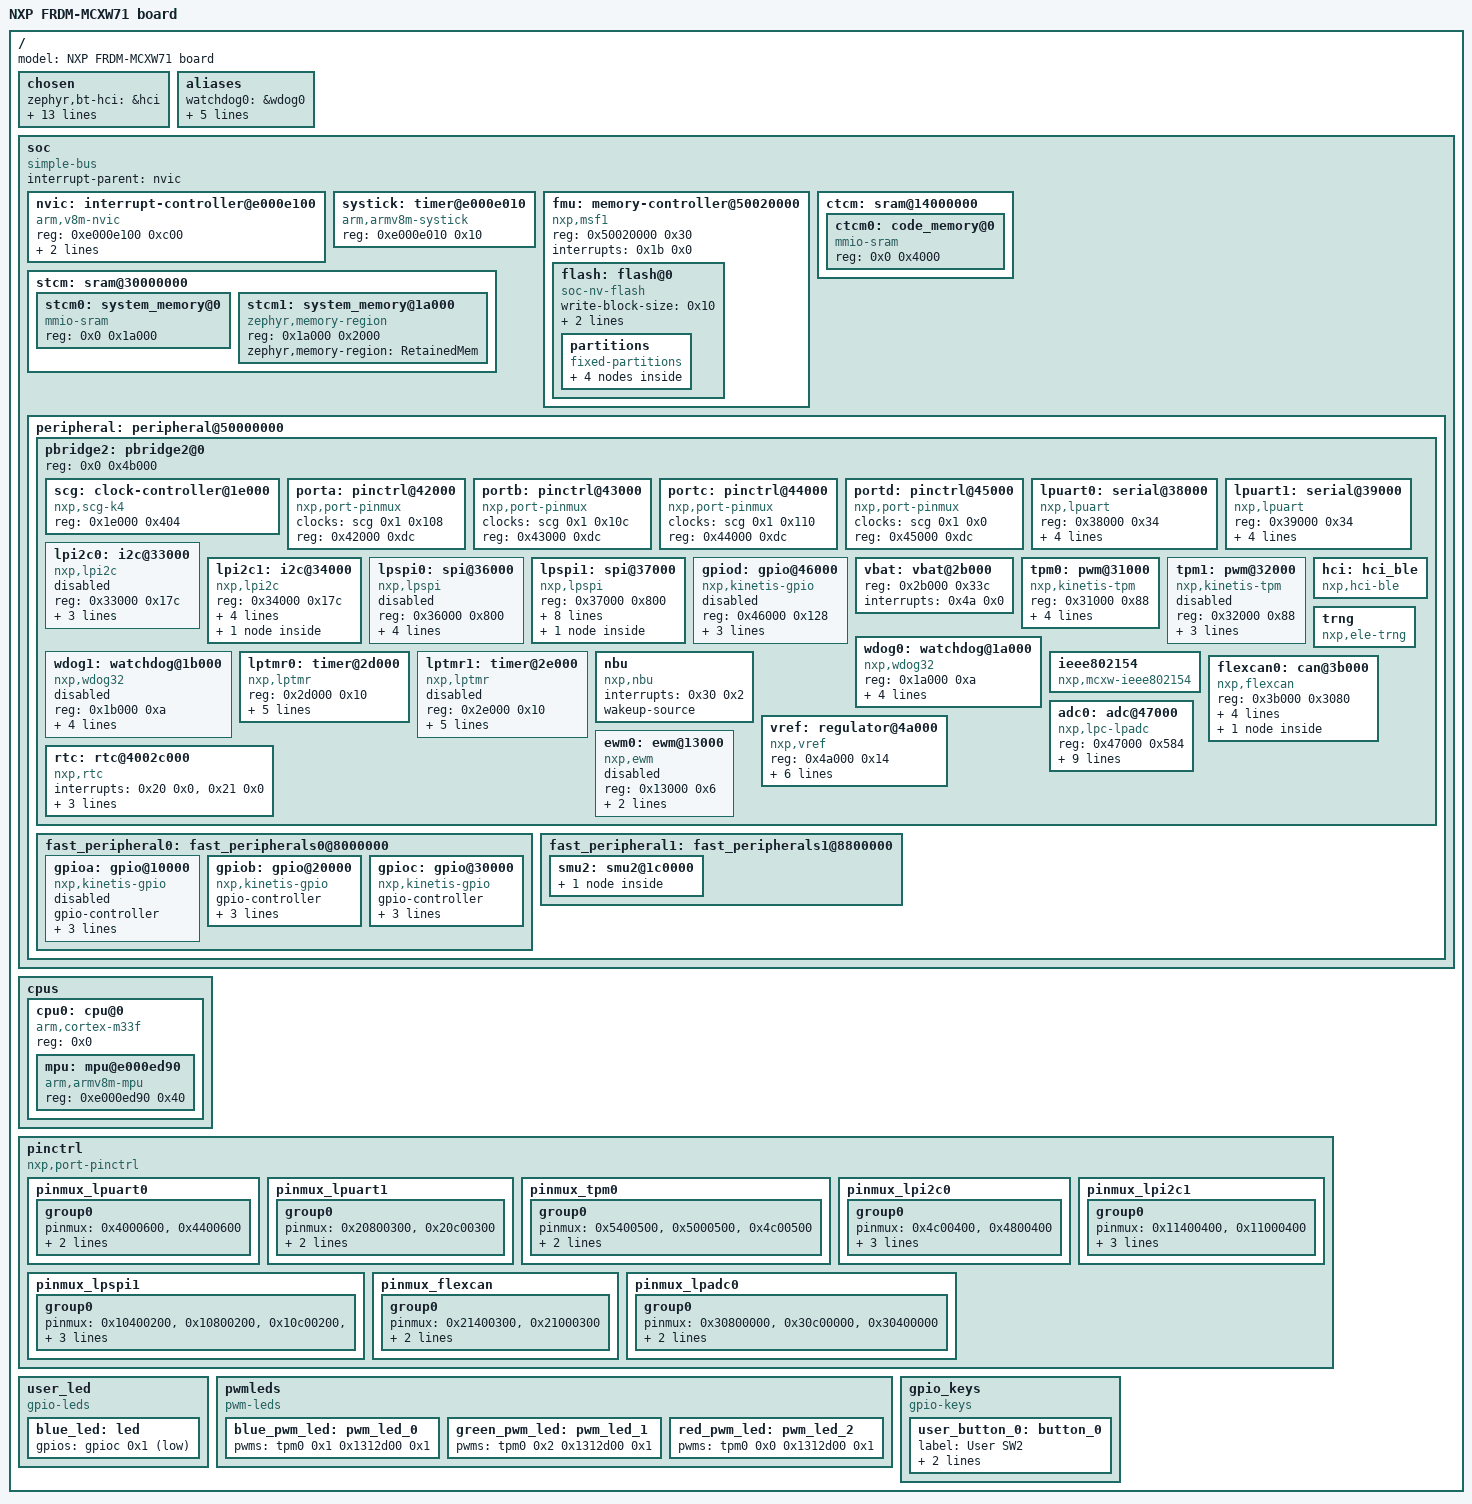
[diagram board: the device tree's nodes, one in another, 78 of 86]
/dts-v1/;

/* node '/' defined in zephyr\dts\common\skeleton.dtsi:9 */
/ {
	#address-cells = < 0x1 >;        /* in zephyr\dts\common\skeleton.dtsi:10 */
	#size-cells = < 0x1 >;           /* in zephyr\dts\common\skeleton.dtsi:11 */
	model = "NXP FRDM-MCXW71 board"; /* in zephyr\boards\nxp\frdm_mcxw71\frdm_mcxw71.dts:13 */

	/* node '/chosen' defined in zephyr\dts\common\skeleton.dtsi:12 */
	chosen {
		zephyr,bt-hci = &hci;                     /* in zephyr\dts\arm\nxp\nxp_mcxw7x_common.dtsi:21 */
		zephyr,ieee802154 = &ieee802154;          /* in zephyr\dts\arm\nxp\nxp_mcxw7x_common.dtsi:22 */
		zephyr,entropy = &trng;                   /* in zephyr\dts\arm\nxp\nxp_mcxw7x_common.dtsi:23 */
		zephyr,nbu = &nbu;                        /* in zephyr\dts\arm\nxp\nxp_mcxw7x_common.dtsi:24 */
		zephyr,flash = &flash;                    /* in zephyr\boards\nxp\frdm_mcxw71\frdm_mcxw71.dts:24 */
		zephyr,flash-controller = &fmu;           /* in zephyr\boards\nxp\frdm_mcxw71\frdm_mcxw71.dts:25 */
		zephyr,code-partition = &slot0_partition; /* in zephyr\boards\nxp\frdm_mcxw71\frdm_mcxw71.dts:26 */
		zephyr,sram = &stcm0;                     /* in zephyr\boards\nxp\frdm_mcxw71\frdm_mcxw71.dts:27 */
		zephyr,console = &lpuart1;                /* in zephyr\boards\nxp\frdm_mcxw71\frdm_mcxw71.dts:28 */
		zephyr,shell-uart = &lpuart1;             /* in zephyr\boards\nxp\frdm_mcxw71\frdm_mcxw71.dts:29 */
		zephyr,uart-pipe = &lpuart0;              /* in zephyr\boards\nxp\frdm_mcxw71\frdm_mcxw71.dts:30 */
		zephyr,canbus = &flexcan0;                /* in zephyr\boards\nxp\frdm_mcxw71\frdm_mcxw71.dts:31 */
		zephyr,uart-mcumgr = &lpuart0;            /* in zephyr\boards\nxp\frdm_mcxw71\frdm_mcxw71.dts:32 */
		zephyr,bt-c2h-uart = &lpuart0;            /* in zephyr\boards\nxp\frdm_mcxw71\frdm_mcxw71.dts:33 */
	};

	/* node '/aliases' defined in zephyr\dts\common\skeleton.dtsi:13 */
	aliases {
		watchdog0 = &wdog0;             /* in zephyr\dts\arm\nxp\nxp_mcxw7x_common.dtsi:17 */
		led0 = &blue_led;               /* in zephyr\boards\nxp\frdm_mcxw71\frdm_mcxw71.dts:16 */
		sw0 = &user_button_0;           /* in zephyr\boards\nxp\frdm_mcxw71\frdm_mcxw71.dts:17 */
		blue-pwm-led = &blue_pwm_led;   /* in zephyr\boards\nxp\frdm_mcxw71\frdm_mcxw71.dts:18 */
		green-pwm-led = &green_pwm_led; /* in zephyr\boards\nxp\frdm_mcxw71\frdm_mcxw71.dts:19 */
		red-pwm-led = &red_pwm_led;     /* in zephyr\boards\nxp\frdm_mcxw71\frdm_mcxw71.dts:20 */
	};

	/* node '/soc' defined in zephyr\dts\arm\armv8-m.dtsi:6 */
	soc {
		#address-cells = < 0x1 >;     /* in zephyr\dts\arm\armv8-m.dtsi:7 */
		#size-cells = < 0x1 >;        /* in zephyr\dts\arm\armv8-m.dtsi:8 */
		compatible = "simple-bus";    /* in zephyr\dts\arm\armv8-m.dtsi:9 */
		interrupt-parent = < &nvic >; /* in zephyr\dts\arm\armv8-m.dtsi:10 */
		ranges;                       /* in zephyr\dts\arm\armv8-m.dtsi:11 */

		/* node '/soc/interrupt-controller@e000e100' defined in zephyr\dts\arm\armv8-m.dtsi:13 */
		nvic: interrupt-controller@e000e100 {
			#address-cells = < 0x1 >;            /* in zephyr\dts\arm\armv8-m.dtsi:14 */
			compatible = "arm,v8m-nvic";         /* in zephyr\dts\arm\armv8-m.dtsi:15 */
			reg = < 0xe000e100 0xc00 >;          /* in zephyr\dts\arm\armv8-m.dtsi:16 */
			interrupt-controller;                /* in zephyr\dts\arm\armv8-m.dtsi:17 */
			#interrupt-cells = < 0x2 >;          /* in zephyr\dts\arm\armv8-m.dtsi:18 */
			arm,num-irq-priority-bits = < 0x3 >; /* in zephyr\dts\arm\nxp\nxp_mcxw7x_common.dtsi:109 */
			phandle = < 0x1 >;                   /* in zephyr\dts\arm\armv8-m.dtsi:10 */
		};

		/* node '/soc/timer@e000e010' defined in zephyr\dts\arm\armv8-m.dtsi:21 */
		systick: timer@e000e010 {
			compatible = "arm,armv8m-systick"; /* in zephyr\dts\arm\armv8-m.dtsi:22 */
			reg = < 0xe000e010 0x10 >;         /* in zephyr\dts\arm\armv8-m.dtsi:23 */
		};

		/* node '/soc/memory-controller@50020000' defined in zephyr\dts\arm\nxp\nxp_mcxw7x_common.dtsi:45 */
		fmu: memory-controller@50020000 {
			#address-cells = < 0x1 >;             /* in zephyr\dts\arm\nxp\nxp_mcxw7x_common.dtsi:46 */
			#size-cells = < 0x1 >;                /* in zephyr\dts\arm\nxp\nxp_mcxw7x_common.dtsi:47 */
			compatible = "nxp,msf1";              /* in zephyr\dts\arm\nxp\nxp_mcxw7x_common.dtsi:48 */
			reg = < 0x50020000 0x30 >;            /* in zephyr\dts\arm\nxp\nxp_mcxw7x_common.dtsi:49 */
			interrupts = < 0x1b 0x0 >;            /* in zephyr\dts\arm\nxp\nxp_mcxw7x_common.dtsi:50 */
			ranges = < 0x0 0x10000000 0x100000 >; /* in zephyr\dts\arm\nxp\nxp_mcxw71.dtsi:10 */
			status = "okay";                      /* in zephyr\boards\nxp\frdm_mcxw71\frdm_mcxw71.dts:159 */

			/* node '/soc/memory-controller@50020000/flash@0' defined in zephyr\dts\arm\nxp\nxp_mcxw7x_common.dtsi:53 */
			flash: flash@0 {
				compatible = "soc-nv-flash";   /* in zephyr\dts\arm\nxp\nxp_mcxw7x_common.dtsi:54 */
				write-block-size = < 0x10 >;   /* in zephyr\dts\arm\nxp\nxp_mcxw7x_common.dtsi:55 */
				erase-block-size = < 0x2000 >; /* in zephyr\dts\arm\nxp\nxp_mcxw7x_common.dtsi:56 */
				reg = < 0x0 0x100000 >;        /* in zephyr\dts\arm\nxp\nxp_mcxw71.dtsi:14 */

				/* node '/soc/memory-controller@50020000/flash@0/partitions' defined in zephyr\boards\nxp\frdm_mcxw71\frdm_mcxw71.dts:134 */
				partitions {
					compatible = "fixed-partitions"; /* in zephyr\boards\nxp\frdm_mcxw71\frdm_mcxw71.dts:135 */
					#address-cells = < 0x1 >;        /* in zephyr\boards\nxp\frdm_mcxw71\frdm_mcxw71.dts:136 */
					#size-cells = < 0x1 >;           /* in zephyr\boards\nxp\frdm_mcxw71\frdm_mcxw71.dts:137 */

					/* node '/soc/memory-controller@50020000/flash@0/partitions/partition@0' defined in zephyr\boards\nxp\frdm_mcxw71\frdm_mcxw71.dts:143 */
					boot_partition: partition@0 {
						reg = < 0x0 0x10000 >; /* in zephyr\boards\nxp\frdm_mcxw71\frdm_mcxw71.dts:144 */
					};

					/* node '/soc/memory-controller@50020000/flash@0/partitions/partition@10000' defined in zephyr\boards\nxp\frdm_mcxw71\frdm_mcxw71.dts:146 */
					slot0_partition: partition@10000 {
						reg = < 0x10000 0x6a000 >; /* in zephyr\boards\nxp\frdm_mcxw71\frdm_mcxw71.dts:147 */
					};

					/* node '/soc/memory-controller@50020000/flash@0/partitions/partition@7A000' defined in zephyr\boards\nxp\frdm_mcxw71\frdm_mcxw71.dts:149 */
					slot1_partition: partition@7A000 {
						reg = < 0x7a000 0x6a000 >; /* in zephyr\boards\nxp\frdm_mcxw71\frdm_mcxw71.dts:150 */
					};

					/* node '/soc/memory-controller@50020000/flash@0/partitions/partition@E4000' defined in zephyr\boards\nxp\frdm_mcxw71\frdm_mcxw71.dts:152 */
					storage_partition: partition@E4000 {
						reg = < 0xe4000 0x1c000 >; /* in zephyr\boards\nxp\frdm_mcxw71\frdm_mcxw71.dts:153 */
					};
				};
			};
		};

		/* node '/soc/sram@14000000' defined in zephyr\dts\arm\nxp\nxp_mcxw7x_common.dtsi:60 */
		ctcm: sram@14000000 {
			#address-cells = < 0x1 >;           /* in zephyr\dts\arm\nxp\nxp_mcxw7x_common.dtsi:61 */
			#size-cells = < 0x1 >;              /* in zephyr\dts\arm\nxp\nxp_mcxw7x_common.dtsi:62 */
			ranges = < 0x0 0x14000000 0x4000 >; /* in zephyr\dts\arm\nxp\nxp_mcxw71.dtsi:18 */

			/* node '/soc/sram@14000000/code_memory@0' defined in zephyr\dts\arm\nxp\nxp_mcxw7x_common.dtsi:64 */
			ctcm0: code_memory@0 {
				compatible = "mmio-sram"; /* in zephyr\dts\arm\nxp\nxp_mcxw7x_common.dtsi:65 */
				reg = < 0x0 0x4000 >;     /* in zephyr\dts\arm\nxp\nxp_mcxw71.dtsi:22 */
			};
		};

		/* node '/soc/sram@30000000' defined in zephyr\dts\arm\nxp\nxp_mcxw7x_common.dtsi:69 */
		stcm: sram@30000000 {
			#address-cells = < 0x1 >;            /* in zephyr\dts\arm\nxp\nxp_mcxw7x_common.dtsi:70 */
			#size-cells = < 0x1 >;               /* in zephyr\dts\arm\nxp\nxp_mcxw7x_common.dtsi:71 */
			ranges = < 0x0 0x30000000 0x1c000 >; /* in zephyr\dts\arm\nxp\nxp_mcxw71.dtsi:26 */

			/* node '/soc/sram@30000000/system_memory@0' defined in zephyr\dts\arm\nxp\nxp_mcxw7x_common.dtsi:73 */
			stcm0: system_memory@0 {
				compatible = "mmio-sram"; /* in zephyr\dts\arm\nxp\nxp_mcxw7x_common.dtsi:74 */
				reg = < 0x0 0x1a000 >;    /* in zephyr\dts\arm\nxp\nxp_mcxw71.dtsi:37 */
			};

			/* node '/soc/sram@30000000/system_memory@1a000' defined in zephyr\dts\arm\nxp\nxp_mcxw71.dtsi:28 */
			stcm1: system_memory@1a000 {
				compatible = "zephyr,memory-region",
				             "mmio-sram";             /* in zephyr\dts\arm\nxp\nxp_mcxw71.dtsi:29 */
				reg = < 0x1a000 0x2000 >;             /* in zephyr\dts\arm\nxp\nxp_mcxw71.dtsi:30 */
				zephyr,memory-region = "RetainedMem"; /* in zephyr\dts\arm\nxp\nxp_mcxw71.dtsi:31 */
			};
		};

		/* node '/soc/peripheral@50000000' defined in zephyr\dts\arm\nxp\nxp_mcxw7x_common.dtsi:78 */
		peripheral: peripheral@50000000 {
			ranges = < 0x0 0x50000000 0x10000000 >; /* in zephyr\dts\arm\nxp\nxp_mcxw7x_common.dtsi:79 */
			#address-cells = < 0x1 >;               /* in zephyr\dts\arm\nxp\nxp_mcxw7x_common.dtsi:80 */
			#size-cells = < 0x1 >;                  /* in zephyr\dts\arm\nxp\nxp_mcxw7x_common.dtsi:81 */

			/* node '/soc/peripheral@50000000/pbridge2@0' defined in zephyr\dts\arm\nxp\nxp_mcxw7x_common.dtsi:83 */
			pbridge2: pbridge2@0 {
				ranges;                   /* in zephyr\dts\arm\nxp\nxp_mcxw7x_common.dtsi:84 */
				#address-cells = < 0x1 >; /* in zephyr\dts\arm\nxp\nxp_mcxw7x_common.dtsi:113 */
				#size-cells = < 0x1 >;    /* in zephyr\dts\arm\nxp\nxp_mcxw7x_common.dtsi:114 */
				reg = < 0x0 0x4b000 >;    /* in zephyr\dts\arm\nxp\nxp_mcxw71.dtsi:41 */

				/* node '/soc/peripheral@50000000/pbridge2@0/clock-controller@1e000' defined in zephyr\dts\arm\nxp\nxp_mcxw7x_common.dtsi:116 */
				scg: clock-controller@1e000 {
					compatible = "nxp,scg-k4"; /* in zephyr\dts\arm\nxp\nxp_mcxw7x_common.dtsi:117 */
					reg = < 0x1e000 0x404 >;   /* in zephyr\dts\arm\nxp\nxp_mcxw7x_common.dtsi:118 */
					#clock-cells = < 0x2 >;    /* in zephyr\dts\arm\nxp\nxp_mcxw7x_common.dtsi:119 */
					phandle = < 0x2 >;         /* in zephyr\dts\arm\nxp\nxp_mcxw7x_common.dtsi:124 */
				};

				/* node '/soc/peripheral@50000000/pbridge2@0/pinctrl@42000' defined in zephyr\dts\arm\nxp\nxp_mcxw7x_common.dtsi:122 */
				porta: pinctrl@42000 {
					compatible = "nxp,port-pinmux"; /* in zephyr\dts\arm\nxp\nxp_mcxw7x_common.dtsi:123 */
					clocks = < &scg 0x1 0x108 >;    /* in zephyr\dts\arm\nxp\nxp_mcxw7x_common.dtsi:124 */
					reg = < 0x42000 0xdc >;         /* in zephyr\dts\arm\nxp\nxp_mcxw71.dtsi:45 */
					phandle = < 0xd >;              /* in zephyr\dts\arm\nxp\nxp_mcxw7x_common.dtsi:362 */
				};

				/* node '/soc/peripheral@50000000/pbridge2@0/pinctrl@43000' defined in zephyr\dts\arm\nxp\nxp_mcxw7x_common.dtsi:127 */
				portb: pinctrl@43000 {
					compatible = "nxp,port-pinmux"; /* in zephyr\dts\arm\nxp\nxp_mcxw7x_common.dtsi:128 */
					clocks = < &scg 0x1 0x10c >;    /* in zephyr\dts\arm\nxp\nxp_mcxw7x_common.dtsi:129 */
					reg = < 0x43000 0xdc >;         /* in zephyr\dts\arm\nxp\nxp_mcxw71.dtsi:49 */
					phandle = < 0xe >;              /* in zephyr\dts\arm\nxp\nxp_mcxw7x_common.dtsi:372 */
				};

				/* node '/soc/peripheral@50000000/pbridge2@0/pinctrl@44000' defined in zephyr\dts\arm\nxp\nxp_mcxw7x_common.dtsi:132 */
				portc: pinctrl@44000 {
					compatible = "nxp,port-pinmux"; /* in zephyr\dts\arm\nxp\nxp_mcxw7x_common.dtsi:133 */
					clocks = < &scg 0x1 0x110 >;    /* in zephyr\dts\arm\nxp\nxp_mcxw7x_common.dtsi:134 */
					reg = < 0x44000 0xdc >;         /* in zephyr\dts\arm\nxp\nxp_mcxw71.dtsi:53 */
					phandle = < 0xf >;              /* in zephyr\dts\arm\nxp\nxp_mcxw7x_common.dtsi:382 */
				};

				/* node '/soc/peripheral@50000000/pbridge2@0/pinctrl@45000' defined in zephyr\dts\arm\nxp\nxp_mcxw7x_common.dtsi:137 */
				portd: pinctrl@45000 {
					compatible = "nxp,port-pinmux"; /* in zephyr\dts\arm\nxp\nxp_mcxw7x_common.dtsi:138 */
					clocks = < &scg 0x1 0x0 >;      /* in zephyr\dts\arm\nxp\nxp_mcxw7x_common.dtsi:139 */
					reg = < 0x45000 0xdc >;         /* in zephyr\dts\arm\nxp\nxp_mcxw71.dtsi:57 */
					phandle = < 0x8 >;              /* in zephyr\dts\arm\nxp\nxp_mcxw7x_common.dtsi:210 */
				};

				/* node '/soc/peripheral@50000000/pbridge2@0/serial@38000' defined in zephyr\dts\arm\nxp\nxp_mcxw7x_common.dtsi:142 */
				lpuart0: serial@38000 {
					compatible = "nxp,lpuart";       /* in zephyr\dts\arm\nxp\nxp_mcxw7x_common.dtsi:143 */
					reg = < 0x38000 0x34 >;          /* in zephyr\dts\arm\nxp\nxp_mcxw7x_common.dtsi:144 */
					interrupts = < 0x2c 0x0 >;       /* in zephyr\dts\arm\nxp\nxp_mcxw7x_common.dtsi:145 */
					clocks = < &scg 0x7 0xe0 >;      /* in zephyr\dts\arm\nxp\nxp_mcxw7x_common.dtsi:146 */
					current-speed = < 0x1c200 >;     /* in zephyr\boards\nxp\frdm_mcxw71\frdm_mcxw71.dts:80 */
					status = "okay";                 /* in zephyr\boards\nxp\frdm_mcxw71\frdm_mcxw71.dts:81 */
					pinctrl-0 = < &pinmux_lpuart0 >; /* in zephyr\boards\nxp\frdm_mcxw71\frdm_mcxw71.dts:82 */
					pinctrl-names = "default";       /* in zephyr\boards\nxp\frdm_mcxw71\frdm_mcxw71.dts:83 */
				};

				/* node '/soc/peripheral@50000000/pbridge2@0/serial@39000' defined in zephyr\dts\arm\nxp\nxp_mcxw7x_common.dtsi:150 */
				lpuart1: serial@39000 {
					compatible = "nxp,lpuart";       /* in zephyr\dts\arm\nxp\nxp_mcxw7x_common.dtsi:151 */
					reg = < 0x39000 0x34 >;          /* in zephyr\dts\arm\nxp\nxp_mcxw7x_common.dtsi:152 */
					interrupts = < 0x2d 0x0 >;       /* in zephyr\dts\arm\nxp\nxp_mcxw7x_common.dtsi:153 */
					clocks = < &scg 0x7 0xe4 >;      /* in zephyr\dts\arm\nxp\nxp_mcxw7x_common.dtsi:154 */
					current-speed = < 0x1c200 >;     /* in zephyr\boards\nxp\frdm_mcxw71\frdm_mcxw71.dts:87 */
					status = "okay";                 /* in zephyr\boards\nxp\frdm_mcxw71\frdm_mcxw71.dts:88 */
					pinctrl-0 = < &pinmux_lpuart1 >; /* in zephyr\boards\nxp\frdm_mcxw71\frdm_mcxw71.dts:89 */
					pinctrl-names = "default";       /* in zephyr\boards\nxp\frdm_mcxw71\frdm_mcxw71.dts:90 */
				};

				/* node '/soc/peripheral@50000000/pbridge2@0/i2c@33000' defined in zephyr\dts\arm\nxp\nxp_mcxw7x_common.dtsi:158 */
				lpi2c0: i2c@33000 {
					compatible = "nxp,lpi2c";      /* in zephyr\dts\arm\nxp\nxp_mcxw7x_common.dtsi:159 */
					reg = < 0x33000 0x17c >;       /* in zephyr\dts\arm\nxp\nxp_mcxw7x_common.dtsi:160 */
					clock-frequency = < 0x186a0 >; /* in zephyr\dts\arm\nxp\nxp_mcxw7x_common.dtsi:161 */
					#address-cells = < 0x1 >;      /* in zephyr\dts\arm\nxp\nxp_mcxw7x_common.dtsi:162 */
					#size-cells = < 0x0 >;         /* in zephyr\dts\arm\nxp\nxp_mcxw7x_common.dtsi:163 */
					interrupts = < 0x27 0x0 >;     /* in zephyr\dts\arm\nxp\nxp_mcxw7x_common.dtsi:164 */
					clocks = < &scg 0x7 0xe0 >;    /* in zephyr\dts\arm\nxp\nxp_mcxw7x_common.dtsi:165 */
					status = "disabled";           /* in zephyr\dts\arm\nxp\nxp_mcxw7x_common.dtsi:166 */
				};

				/* node '/soc/peripheral@50000000/pbridge2@0/i2c@34000' defined in zephyr\dts\arm\nxp\nxp_mcxw7x_common.dtsi:169 */
				lpi2c1: i2c@34000 {
					compatible = "nxp,lpi2c";       /* in zephyr\dts\arm\nxp\nxp_mcxw7x_common.dtsi:170 */
					reg = < 0x34000 0x17c >;        /* in zephyr\dts\arm\nxp\nxp_mcxw7x_common.dtsi:171 */
					clock-frequency = < 0x186a0 >;  /* in zephyr\dts\arm\nxp\nxp_mcxw7x_common.dtsi:172 */
					#address-cells = < 0x1 >;       /* in zephyr\dts\arm\nxp\nxp_mcxw7x_common.dtsi:173 */
					#size-cells = < 0x0 >;          /* in zephyr\dts\arm\nxp\nxp_mcxw7x_common.dtsi:174 */
					interrupts = < 0x28 0x0 >;      /* in zephyr\dts\arm\nxp\nxp_mcxw7x_common.dtsi:175 */
					clocks = < &scg 0x7 0xe4 >;     /* in zephyr\dts\arm\nxp\nxp_mcxw7x_common.dtsi:176 */
					status = "okay";                /* in zephyr\boards\nxp\frdm_mcxw71\frdm_mcxw71.dts:94 */
					pinctrl-0 = < &pinmux_lpi2c1 >; /* in zephyr\boards\nxp\frdm_mcxw71\frdm_mcxw71.dts:95 */
					pinctrl-names = "default";      /* in zephyr\boards\nxp\frdm_mcxw71\frdm_mcxw71.dts:96 */

					/* node '/soc/peripheral@50000000/pbridge2@0/i2c@34000/accelerometer@19' defined in zephyr\boards\nxp\frdm_mcxw71\frdm_mcxw71.dts:98 */
					accelerometer: accelerometer@19 {
						status = "okay";             /* in zephyr\boards\nxp\frdm_mcxw71\frdm_mcxw71.dts:99 */
						compatible = "nxp,fxls8974"; /* in zephyr\boards\nxp\frdm_mcxw71\frdm_mcxw71.dts:100 */
						reg = < 0x19 >;              /* in zephyr\boards\nxp\frdm_mcxw71\frdm_mcxw71.dts:101 */
					};
				};

				/* node '/soc/peripheral@50000000/pbridge2@0/spi@36000' defined in zephyr\dts\arm\nxp\nxp_mcxw7x_common.dtsi:180 */
				lpspi0: spi@36000 {
					compatible = "nxp,lpspi";   /* in zephyr\dts\arm\nxp\nxp_mcxw7x_common.dtsi:181 */
					reg = < 0x36000 0x800 >;    /* in zephyr\dts\arm\nxp\nxp_mcxw7x_common.dtsi:182 */
					interrupts = < 0x2a 0x0 >;  /* in zephyr\dts\arm\nxp\nxp_mcxw7x_common.dtsi:183 */
					clocks = < &scg 0x7 0xd8 >; /* in zephyr\dts\arm\nxp\nxp_mcxw7x_common.dtsi:184 */
					tx-fifo-size = < 0x8 >;     /* in zephyr\dts\arm\nxp\nxp_mcxw7x_common.dtsi:185 */
					rx-fifo-size = < 0x8 >;     /* in zephyr\dts\arm\nxp\nxp_mcxw7x_common.dtsi:186 */
					#address-cells = < 0x1 >;   /* in zephyr\dts\arm\nxp\nxp_mcxw7x_common.dtsi:187 */
					#size-cells = < 0x0 >;      /* in zephyr\dts\arm\nxp\nxp_mcxw7x_common.dtsi:188 */
					status = "disabled";        /* in zephyr\dts\arm\nxp\nxp_mcxw7x_common.dtsi:189 */
				};

				/* node '/soc/peripheral@50000000/pbridge2@0/spi@37000' defined in zephyr\dts\arm\nxp\nxp_mcxw7x_common.dtsi:192 */
				lpspi1: spi@37000 {
					compatible = "nxp,lpspi";       /* in zephyr\dts\arm\nxp\nxp_mcxw7x_common.dtsi:193 */
					reg = < 0x37000 0x800 >;        /* in zephyr\dts\arm\nxp\nxp_mcxw7x_common.dtsi:194 */
					interrupts = < 0x2b 0x0 >;      /* in zephyr\dts\arm\nxp\nxp_mcxw7x_common.dtsi:195 */
					clocks = < &scg 0x7 0xdc >;     /* in zephyr\dts\arm\nxp\nxp_mcxw7x_common.dtsi:196 */
					tx-fifo-size = < 0x8 >;         /* in zephyr\dts\arm\nxp\nxp_mcxw7x_common.dtsi:197 */
					rx-fifo-size = < 0x8 >;         /* in zephyr\dts\arm\nxp\nxp_mcxw7x_common.dtsi:198 */
					#address-cells = < 0x1 >;       /* in zephyr\dts\arm\nxp\nxp_mcxw7x_common.dtsi:199 */
					#size-cells = < 0x0 >;          /* in zephyr\dts\arm\nxp\nxp_mcxw7x_common.dtsi:200 */
					status = "okay";                /* in zephyr\boards\nxp\frdm_mcxw71\frdm_mcxw71.dts:106 */
					pinctrl-0 = < &pinmux_lpspi1 >; /* in zephyr\boards\nxp\frdm_mcxw71\frdm_mcxw71.dts:107 */
					pinctrl-names = "default";      /* in zephyr\boards\nxp\frdm_mcxw71\frdm_mcxw71.dts:108 */
					pcs-sck-delay = < 0x5 >;        /* in zephyr\boards\nxp\frdm_mcxw71\frdm_mcxw71.dts:109 */
					sck-pcs-delay = < 0x5 >;        /* in zephyr\boards\nxp\frdm_mcxw71\frdm_mcxw71.dts:110 */
					transfer-delay = < 0x7d >;      /* in zephyr\boards\nxp\frdm_mcxw71\frdm_mcxw71.dts:111 */

					/* node '/soc/peripheral@50000000/pbridge2@0/spi@37000/flash@0' defined in zephyr\boards\nxp\frdm_mcxw71\frdm_mcxw71.dts:113 */
					mx25r6435fm2il0: flash@0 {
						compatible = "jedec,spi-nor";                 /* in zephyr\boards\nxp\frdm_mcxw71\frdm_mcxw71.dts:114 */
						jedec-id = [ C2 28 17 ];                      /* in zephyr\boards\nxp\frdm_mcxw71\frdm_mcxw71.dts:115 */
						reg = < 0x0 >;                                /* in zephyr\boards\nxp\frdm_mcxw71\frdm_mcxw71.dts:116 */
						wp-gpios = < &gpioc 0x0 0x1 >;                /* in zephyr\boards\nxp\frdm_mcxw71\frdm_mcxw71.dts:121 */
						size = < 0x4000000 >;                         /* in zephyr\boards\nxp\frdm_mcxw71\frdm_mcxw71.dts:122 */
						has-dpd;                                      /* in zephyr\boards\nxp\frdm_mcxw71\frdm_mcxw71.dts:123 */
						dpd-wakeup-sequence = < 0x7530 0x14 0x88b8 >; /* in zephyr\boards\nxp\frdm_mcxw71\frdm_mcxw71.dts:124 */
						t-enter-dpd = < 0x2710 >;                     /* in zephyr\boards\nxp\frdm_mcxw71\frdm_mcxw71.dts:125 */
						mxicy,mx25r-power-mode = "low-power";         /* in zephyr\boards\nxp\frdm_mcxw71\frdm_mcxw71.dts:127 */
						spi-max-frequency = < 0x7a1200 >;             /* in zephyr\boards\nxp\frdm_mcxw71\frdm_mcxw71.dts:129 */
					};
				};

				/* node '/soc/peripheral@50000000/pbridge2@0/gpio@46000' defined in zephyr\dts\arm\nxp\nxp_mcxw7x_common.dtsi:204 */
				gpiod: gpio@46000 {
					compatible = "nxp,kinetis-gpio"; /* in zephyr\dts\arm\nxp\nxp_mcxw7x_common.dtsi:205 */
					reg = < 0x46000 0x128 >;         /* in zephyr\dts\arm\nxp\nxp_mcxw7x_common.dtsi:206 */
					interrupts = < 0x41 0x0 >,
					             < 0x42 0x0 >;       /* in zephyr\dts\arm\nxp\nxp_mcxw7x_common.dtsi:207 */
					gpio-controller;                 /* in zephyr\dts\arm\nxp\nxp_mcxw7x_common.dtsi:208 */
					#gpio-cells = < 0x2 >;           /* in zephyr\dts\arm\nxp\nxp_mcxw7x_common.dtsi:209 */
					nxp,kinetis-port = < &portd >;   /* in zephyr\dts\arm\nxp\nxp_mcxw7x_common.dtsi:210 */
					status = "disabled";             /* in zephyr\dts\arm\nxp\nxp_mcxw7x_common.dtsi:211 */
				};

				/* node '/soc/peripheral@50000000/pbridge2@0/vbat@2b000' defined in zephyr\dts\arm\nxp\nxp_mcxw7x_common.dtsi:214 */
				vbat: vbat@2b000 {
					reg = < 0x2b000 0x33c >;   /* in zephyr\dts\arm\nxp\nxp_mcxw7x_common.dtsi:215 */
					interrupts = < 0x4a 0x0 >; /* in zephyr\dts\arm\nxp\nxp_mcxw7x_common.dtsi:216 */
				};

				/* node '/soc/peripheral@50000000/pbridge2@0/pwm@31000' defined in zephyr\dts\arm\nxp\nxp_mcxw7x_common.dtsi:219 */
				tpm0: pwm@31000 {
					compatible = "nxp,kinetis-tpm"; /* in zephyr\dts\arm\nxp\nxp_mcxw7x_common.dtsi:220 */
					reg = < 0x31000 0x88 >;         /* in zephyr\dts\arm\nxp\nxp_mcxw7x_common.dtsi:221 */
					interrupts = < 0x25 0x0 >;      /* in zephyr\dts\arm\nxp\nxp_mcxw7x_common.dtsi:222 */
					clocks = < &scg 0x7 0xc4 >;     /* in zephyr\dts\arm\nxp\nxp_mcxw7x_common.dtsi:223 */
					prescaler = < 0x10 >;           /* in zephyr\dts\arm\nxp\nxp_mcxw7x_common.dtsi:224 */
					#pwm-cells = < 0x3 >;           /* in zephyr\dts\arm\nxp\nxp_mcxw7x_common.dtsi:226 */
					status = "okay";                /* in zephyr\boards\nxp\frdm_mcxw71\frdm_mcxw71.dts:163 */
					pinctrl-0 = < &pinmux_tpm0 >;   /* in zephyr\boards\nxp\frdm_mcxw71\frdm_mcxw71.dts:164 */
					pinctrl-names = "default";      /* in zephyr\boards\nxp\frdm_mcxw71\frdm_mcxw71.dts:165 */
					phandle = < 0x10 >;             /* in zephyr\boards\nxp\frdm_mcxw71\frdm_mcxw71.dts:46 */
				};

				/* node '/soc/peripheral@50000000/pbridge2@0/pwm@32000' defined in zephyr\dts\arm\nxp\nxp_mcxw7x_common.dtsi:229 */
				tpm1: pwm@32000 {
					compatible = "nxp,kinetis-tpm"; /* in zephyr\dts\arm\nxp\nxp_mcxw7x_common.dtsi:230 */
					reg = < 0x32000 0x88 >;         /* in zephyr\dts\arm\nxp\nxp_mcxw7x_common.dtsi:231 */
					interrupts = < 0x26 0x0 >;      /* in zephyr\dts\arm\nxp\nxp_mcxw7x_common.dtsi:232 */
					clocks = < &scg 0x7 0xc8 >;     /* in zephyr\dts\arm\nxp\nxp_mcxw7x_common.dtsi:233 */
					prescaler = < 0x10 >;           /* in zephyr\dts\arm\nxp\nxp_mcxw7x_common.dtsi:234 */
					status = "disabled";            /* in zephyr\dts\arm\nxp\nxp_mcxw7x_common.dtsi:235 */
					#pwm-cells = < 0x3 >;           /* in zephyr\dts\arm\nxp\nxp_mcxw7x_common.dtsi:236 */
				};

				/* node '/soc/peripheral@50000000/pbridge2@0/watchdog@1a000' defined in zephyr\dts\arm\nxp\nxp_mcxw7x_common.dtsi:239 */
				wdog0: watchdog@1a000 {
					compatible = "nxp,wdog32";  /* in zephyr\dts\arm\nxp\nxp_mcxw7x_common.dtsi:240 */
					reg = < 0x1a000 0xa >;      /* in zephyr\dts\arm\nxp\nxp_mcxw7x_common.dtsi:241 */
					interrupts = < 0x17 0x0 >;  /* in zephyr\dts\arm\nxp\nxp_mcxw7x_common.dtsi:242 */
					clocks = < &scg 0x5 0x68 >; /* in zephyr\dts\arm\nxp\nxp_mcxw7x_common.dtsi:243 */
					clk-source = < 0x1 >;       /* in zephyr\dts\arm\nxp\nxp_mcxw7x_common.dtsi:244 */
					clk-divider = < 0x100 >;    /* in zephyr\dts\arm\nxp\nxp_mcxw7x_common.dtsi:245 */
					status = "okay";            /* in zephyr\dts\arm\nxp\nxp_mcxw7x_common.dtsi:246 */
				};

				/* node '/soc/peripheral@50000000/pbridge2@0/watchdog@1b000' defined in zephyr\dts\arm\nxp\nxp_mcxw7x_common.dtsi:249 */
				wdog1: watchdog@1b000 {
					compatible = "nxp,wdog32";  /* in zephyr\dts\arm\nxp\nxp_mcxw7x_common.dtsi:250 */
					reg = < 0x1b000 0xa >;      /* in zephyr\dts\arm\nxp\nxp_mcxw7x_common.dtsi:251 */
					interrupts = < 0x18 0x0 >;  /* in zephyr\dts\arm\nxp\nxp_mcxw7x_common.dtsi:252 */
					clocks = < &scg 0x5 0x6c >; /* in zephyr\dts\arm\nxp\nxp_mcxw7x_common.dtsi:253 */
					clk-source = < 0x1 >;       /* in zephyr\dts\arm\nxp\nxp_mcxw7x_common.dtsi:254 */
					clk-divider = < 0x100 >;    /* in zephyr\dts\arm\nxp\nxp_mcxw7x_common.dtsi:255 */
					status = "disabled";        /* in zephyr\dts\arm\nxp\nxp_mcxw7x_common.dtsi:256 */
				};

				/* node '/soc/peripheral@50000000/pbridge2@0/timer@2d000' defined in zephyr\dts\arm\nxp\nxp_mcxw7x_common.dtsi:259 */
				lptmr0: timer@2d000 {
					compatible = "nxp,lptmr";     /* in zephyr\dts\arm\nxp\nxp_mcxw7x_common.dtsi:260 */
					reg = < 0x2d000 0x10 >;       /* in zephyr\dts\arm\nxp\nxp_mcxw7x_common.dtsi:261 */
					interrupts = < 0x22 0x0 >;    /* in zephyr\dts\arm\nxp\nxp_mcxw7x_common.dtsi:262 */
					clock-frequency = < 0x7d00 >; /* in zephyr\dts\arm\nxp\nxp_mcxw7x_common.dtsi:263 */
					clk-source = < 0x2 >;         /* in zephyr\dts\arm\nxp\nxp_mcxw7x_common.dtsi:264 */
					prescaler = < 0x1 >;          /* in zephyr\dts\arm\nxp\nxp_mcxw7x_common.dtsi:265 */
					resolution = < 0x20 >;        /* in zephyr\dts\arm\nxp\nxp_mcxw7x_common.dtsi:266 */
					status = "okay";              /* in zephyr\boards\nxp\frdm_mcxw71\frdm_mcxw71.dts:169 */
				};

				/* node '/soc/peripheral@50000000/pbridge2@0/timer@2e000' defined in zephyr\dts\arm\nxp\nxp_mcxw7x_common.dtsi:270 */
				lptmr1: timer@2e000 {
					compatible = "nxp,lptmr";     /* in zephyr\dts\arm\nxp\nxp_mcxw7x_common.dtsi:271 */
					reg = < 0x2e000 0x10 >;       /* in zephyr\dts\arm\nxp\nxp_mcxw7x_common.dtsi:272 */
					interrupts = < 0x23 0x0 >;    /* in zephyr\dts\arm\nxp\nxp_mcxw7x_common.dtsi:273 */
					clock-frequency = < 0x7d00 >; /* in zephyr\dts\arm\nxp\nxp_mcxw7x_common.dtsi:274 */
					clk-source = < 0x2 >;         /* in zephyr\dts\arm\nxp\nxp_mcxw7x_common.dtsi:275 */
					prescaler = < 0x1 >;          /* in zephyr\dts\arm\nxp\nxp_mcxw7x_common.dtsi:276 */
					resolution = < 0x20 >;        /* in zephyr\dts\arm\nxp\nxp_mcxw7x_common.dtsi:277 */
					status = "disabled";          /* in zephyr\dts\arm\nxp\nxp_mcxw7x_common.dtsi:278 */
				};

				/* node '/soc/peripheral@50000000/pbridge2@0/nbu' defined in zephyr\dts\arm\nxp\nxp_mcxw7x_common.dtsi:281 */
				nbu: nbu {
					compatible = "nxp,nbu";         /* in zephyr\dts\arm\nxp\nxp_mcxw7x_common.dtsi:282 */
					interrupts = < 0x30 0x2 >;      /* in zephyr\dts\arm\nxp\nxp_mcxw7x_common.dtsi:283 */
					interrupt-names = "nbu_rx_int"; /* in zephyr\dts\arm\nxp\nxp_mcxw7x_common.dtsi:284 */
					status = "okay";                /* in zephyr\boards\nxp\frdm_mcxw71\frdm_mcxw71.dts:189 */
					wakeup-source;                  /* in zephyr\boards\nxp\frdm_mcxw71\frdm_mcxw71.dts:190 */
				};

				/* node '/soc/peripheral@50000000/pbridge2@0/hci_ble' defined in zephyr\dts\arm\nxp\nxp_mcxw7x_common.dtsi:287 */
				hci: hci_ble {
					compatible = "nxp,hci-ble"; /* in zephyr\dts\arm\nxp\nxp_mcxw7x_common.dtsi:288 */
				};

				/* node '/soc/peripheral@50000000/pbridge2@0/ieee802154' defined in zephyr\dts\arm\nxp\nxp_mcxw7x_common.dtsi:291 */
				ieee802154: ieee802154 {
					compatible = "nxp,mcxw-ieee802154"; /* in zephyr\dts\arm\nxp\nxp_mcxw7x_common.dtsi:292 */
				};

				/* node '/soc/peripheral@50000000/pbridge2@0/trng' defined in zephyr\dts\arm\nxp\nxp_mcxw7x_common.dtsi:295 */
				trng: trng {
					compatible = "nxp,ele-trng"; /* in zephyr\dts\arm\nxp\nxp_mcxw7x_common.dtsi:296 */
				};

				/* node '/soc/peripheral@50000000/pbridge2@0/can@3b000' defined in zephyr\dts\arm\nxp\nxp_mcxw7x_common.dtsi:299 */
				flexcan0: can@3b000 {
					compatible = "nxp,flexcan";      /* in zephyr\dts\arm\nxp\nxp_mcxw7x_common.dtsi:300 */
					reg = < 0x3b000 0x3080 >;        /* in zephyr\dts\arm\nxp\nxp_mcxw7x_common.dtsi:301 */
					interrupts = < 0x2f 0x0 >;       /* in zephyr\dts\arm\nxp\nxp_mcxw7x_common.dtsi:302 */
					interrupt-names = "common";      /* in zephyr\dts\arm\nxp\nxp_mcxw7x_common.dtsi:303 */
					clocks = < &scg 0x7 0xec >;      /* in zephyr\dts\arm\nxp\nxp_mcxw7x_common.dtsi:304 */
					clk-source = < 0x2 >;            /* in zephyr\dts\arm\nxp\nxp_mcxw7x_common.dtsi:305 */
					status = "okay";                 /* in zephyr\boards\nxp\frdm_mcxw71\frdm_mcxw71.dts:173 */
					pinctrl-0 = < &pinmux_flexcan >; /* in zephyr\boards\nxp\frdm_mcxw71\frdm_mcxw71.dts:174 */
					pinctrl-names = "default";       /* in zephyr\boards\nxp\frdm_mcxw71\frdm_mcxw71.dts:175 */

					/* node '/soc/peripheral@50000000/pbridge2@0/can@3b000/can-transceiver' defined in zephyr\boards\nxp\frdm_mcxw71\frdm_mcxw71.dts:177 */
					can-transceiver {
						max-bitrate = < 0x4c4b40 >; /* in zephyr\boards\nxp\frdm_mcxw71\frdm_mcxw71.dts:178 */
					};
				};

				/* node '/soc/peripheral@50000000/pbridge2@0/adc@47000' defined in zephyr\dts\arm\nxp\nxp_mcxw7x_common.dtsi:309 */
				adc0: adc@47000 {
					compatible = "nxp,lpc-lpadc";     /* in zephyr\dts\arm\nxp\nxp_mcxw7x_common.dtsi:310 */
					reg = < 0x47000 0x584 >;          /* in zephyr\dts\arm\nxp\nxp_mcxw7x_common.dtsi:311 */
					interrupts = < 0x47 0x0 >;        /* in zephyr\dts\arm\nxp\nxp_mcxw7x_common.dtsi:312 */
					clocks = < &scg 0x7 0x11c >;      /* in zephyr\dts\arm\nxp\nxp_mcxw7x_common.dtsi:313 */
					voltage-ref = < 0x1 >;            /* in zephyr\dts\arm\nxp\nxp_mcxw7x_common.dtsi:314 */
					calibration-average = < 0x80 >;   /* in zephyr\dts\arm\nxp\nxp_mcxw7x_common.dtsi:315 */
					power-level = < 0x0 >;            /* in zephyr\dts\arm\nxp\nxp_mcxw7x_common.dtsi:317 */
					offset-value-a = < 0x0 >;         /* in zephyr\dts\arm\nxp\nxp_mcxw7x_common.dtsi:318 */
					offset-value-b = < 0x0 >;         /* in zephyr\dts\arm\nxp\nxp_mcxw7x_common.dtsi:319 */
					#io-channel-cells = < 0x1 >;      /* in zephyr\dts\arm\nxp\nxp_mcxw7x_common.dtsi:320 */
					nxp,references = < &vref 0x708 >; /* in zephyr\dts\arm\nxp\nxp_mcxw7x_common.dtsi:321 */
					pinctrl-0 = < &pinmux_lpadc0 >;   /* in zephyr\boards\nxp\frdm_mcxw71\frdm_mcxw71.dts:183 */
					pinctrl-names = "default";        /* in zephyr\boards\nxp\frdm_mcxw71\frdm_mcxw71.dts:184 */
					status = "okay";                  /* in zephyr\boards\nxp\frdm_mcxw71\frdm_mcxw71.dts:185 */
				};

				/* node '/soc/peripheral@50000000/pbridge2@0/regulator@4a000' defined in zephyr\dts\arm\nxp\nxp_mcxw7x_common.dtsi:325 */
				vref: regulator@4a000 {
					compatible = "nxp,vref";                 /* in zephyr\dts\arm\nxp\nxp_mcxw7x_common.dtsi:326 */
					reg = < 0x4a000 0x14 >;                  /* in zephyr\dts\arm\nxp\nxp_mcxw7x_common.dtsi:327 */
					regulator-name = "mcxw71-vref";          /* in zephyr\dts\arm\nxp\nxp_mcxw7x_common.dtsi:328 */
					#nxp,reference-cells = < 0x1 >;          /* in zephyr\dts\arm\nxp\nxp_mcxw7x_common.dtsi:329 */
					nxp,buffer-startup-delay-us = < 0x190 >; /* in zephyr\dts\arm\nxp\nxp_mcxw7x_common.dtsi:330 */
					nxp,bandgap-startup-time-us = < 0x14 >;  /* in zephyr\dts\arm\nxp\nxp_mcxw7x_common.dtsi:331 */
					regulator-min-microvolt = < 0xf4240 >;   /* in zephyr\dts\arm\nxp\nxp_mcxw7x_common.dtsi:332 */
					regulator-max-microvolt = < 0x200b20 >;  /* in zephyr\dts\arm\nxp\nxp_mcxw7x_common.dtsi:333 */
					nxp,current-compensation-en;             /* in zephyr\dts\arm\nxp\nxp_mcxw7x_common.dtsi:334 */
					status = "okay";                         /* in zephyr\boards\nxp\frdm_mcxw71\frdm_mcxw71.dts:68 */
					phandle = < 0xb >;                       /* in zephyr\dts\arm\nxp\nxp_mcxw7x_common.dtsi:321 */
				};

				/* node '/soc/peripheral@50000000/pbridge2@0/rtc@4002c000' defined in zephyr\dts\arm\nxp\nxp_mcxw7x_common.dtsi:338 */
				rtc: rtc@4002c000 {
					compatible = "nxp,rtc";       /* in zephyr\dts\arm\nxp\nxp_mcxw7x_common.dtsi:339 */
					interrupts = < 0x20 0x0 >,
					             < 0x21 0x0 >;    /* in zephyr\dts\arm\nxp\nxp_mcxw7x_common.dtsi:341 */
					interrupt-names = "alarm",
					                  "seconds";  /* in zephyr\dts\arm\nxp\nxp_mcxw7x_common.dtsi:342 */
					clock-frequency = < 0x8000 >; /* in zephyr\dts\arm\nxp\nxp_mcxw7x_common.dtsi:343 */
					prescaler = < 0x8000 >;       /* in zephyr\dts\arm\nxp\nxp_mcxw7x_common.dtsi:344 */
					reg = < 0x4002c000 0x50 >;    /* in zephyr\dts\arm\nxp\nxp_mcxw71.dtsi:65 */
					status = "okay";              /* in zephyr\boards\nxp\frdm_mcxw71\frdm_mcxw71.dts:194 */
				};

				/* node '/soc/peripheral@50000000/pbridge2@0/ewm@13000' defined in zephyr\dts\arm\nxp\nxp_mcxw7x_common.dtsi:347 */
				ewm0: ewm@13000 {
					compatible = "nxp,ewm";    /* in zephyr\dts\arm\nxp\nxp_mcxw7x_common.dtsi:348 */
					reg = < 0x13000 0x6 >;     /* in zephyr\dts\arm\nxp\nxp_mcxw7x_common.dtsi:349 */
					status = "disabled";       /* in zephyr\dts\arm\nxp\nxp_mcxw7x_common.dtsi:350 */
					interrupts = < 0x12 0x0 >; /* in zephyr\dts\arm\nxp\nxp_mcxw7x_common.dtsi:351 */
					clk-divider = < 0x0 >;     /* in zephyr\dts\arm\nxp\nxp_mcxw7x_common.dtsi:352 */
				};
			};

			/* node '/soc/peripheral@50000000/fast_peripherals0@8000000' defined in zephyr\dts\arm\nxp\nxp_mcxw7x_common.dtsi:89 */
			fast_peripheral0: fast_peripherals0@8000000 {
				#address-cells = < 0x1 >;           /* in zephyr\dts\arm\nxp\nxp_mcxw7x_common.dtsi:90 */
				#size-cells = < 0x1 >;              /* in zephyr\dts\arm\nxp\nxp_mcxw7x_common.dtsi:91 */
				ranges = < 0x0 0x8000000 0x40000 >; /* in zephyr\dts\arm\nxp\nxp_mcxw7x_common.dtsi:92 */

				/* node '/soc/peripheral@50000000/fast_peripherals0@8000000/gpio@10000' defined in zephyr\dts\arm\nxp\nxp_mcxw7x_common.dtsi:357 */
				gpioa: gpio@10000 {
					compatible = "nxp,kinetis-gpio"; /* in zephyr\dts\arm\nxp\nxp_mcxw7x_common.dtsi:358 */
					status = "disabled";             /* in zephyr\dts\arm\nxp\nxp_mcxw7x_common.dtsi:359 */
					gpio-controller;                 /* in zephyr\dts\arm\nxp\nxp_mcxw7x_common.dtsi:360 */
					#gpio-cells = < 0x2 >;           /* in zephyr\dts\arm\nxp\nxp_mcxw7x_common.dtsi:361 */
					nxp,kinetis-port = < &porta >;   /* in zephyr\dts\arm\nxp\nxp_mcxw7x_common.dtsi:362 */
					reg = < 0x10000 0x128 >;         /* in zephyr\dts\arm\nxp\nxp_mcxw7x_common.dtsi:363 */
					interrupts = < 0x3b 0x0 >,
					             < 0x3c 0x0 >;       /* in zephyr\dts\arm\nxp\nxp_mcxw7x_common.dtsi:364 */
				};

				/* node '/soc/peripheral@50000000/fast_peripherals0@8000000/gpio@20000' defined in zephyr\dts\arm\nxp\nxp_mcxw7x_common.dtsi:367 */
				gpiob: gpio@20000 {
					compatible = "nxp,kinetis-gpio"; /* in zephyr\dts\arm\nxp\nxp_mcxw7x_common.dtsi:368 */
					gpio-controller;                 /* in zephyr\dts\arm\nxp\nxp_mcxw7x_common.dtsi:370 */
					#gpio-cells = < 0x2 >;           /* in zephyr\dts\arm\nxp\nxp_mcxw7x_common.dtsi:371 */
					nxp,kinetis-port = < &portb >;   /* in zephyr\dts\arm\nxp\nxp_mcxw7x_common.dtsi:372 */
					reg = < 0x20000 0x128 >;         /* in zephyr\dts\arm\nxp\nxp_mcxw7x_common.dtsi:373 */
					interrupts = < 0x3d 0x0 >,
					             < 0x3e 0x0 >;       /* in zephyr\dts\arm\nxp\nxp_mcxw7x_common.dtsi:374 */
					status = "okay";                 /* in zephyr\boards\nxp\frdm_mcxw71\frdm_mcxw71.dts:72 */
				};

				/* node '/soc/peripheral@50000000/fast_peripherals0@8000000/gpio@30000' defined in zephyr\dts\arm\nxp\nxp_mcxw7x_common.dtsi:377 */
				gpioc: gpio@30000 {
					compatible = "nxp,kinetis-gpio"; /* in zephyr\dts\arm\nxp\nxp_mcxw7x_common.dtsi:378 */
					gpio-controller;                 /* in zephyr\dts\arm\nxp\nxp_mcxw7x_common.dtsi:380 */
					#gpio-cells = < 0x2 >;           /* in zephyr\dts\arm\nxp\nxp_mcxw7x_common.dtsi:381 */
					nxp,kinetis-port = < &portc >;   /* in zephyr\dts\arm\nxp\nxp_mcxw7x_common.dtsi:382 */
					reg = < 0x30000 0x128 >;         /* in zephyr\dts\arm\nxp\nxp_mcxw7x_common.dtsi:383 */
					interrupts = < 0x3f 0x0 >,
					             < 0x40 0x0 >;       /* in zephyr\dts\arm\nxp\nxp_mcxw7x_common.dtsi:384 */
					status = "okay";                 /* in zephyr\boards\nxp\frdm_mcxw71\frdm_mcxw71.dts:76 */
					phandle = < 0x7 >;               /* in zephyr\boards\nxp\frdm_mcxw71\frdm_mcxw71.dts:121 */
				};
			};

			/* node '/soc/peripheral@50000000/fast_peripherals1@8800000' defined in zephyr\dts\arm\nxp\nxp_mcxw7x_common.dtsi:95 */
			fast_peripheral1: fast_peripherals1@8800000 {
				#address-cells = < 0x1 >;            /* in zephyr\dts\arm\nxp\nxp_mcxw7x_common.dtsi:96 */
				#size-cells = < 0x1 >;               /* in zephyr\dts\arm\nxp\nxp_mcxw7x_common.dtsi:97 */
				ranges = < 0x0 0x8800000 0x20a000 >; /* in zephyr\dts\arm\nxp\nxp_mcxw7x_common.dtsi:98 */

				/* node '/soc/peripheral@50000000/fast_peripherals1@8800000/smu2@1c0000' defined in zephyr\dts\arm\nxp\nxp_mcxw7x_common.dtsi:389 */
				smu2: smu2@1c0000 {
					#address-cells = < 0x1 >;         /* in zephyr\dts\arm\nxp\nxp_mcxw7x_common.dtsi:390 */
					#size-cells = < 0x1 >;            /* in zephyr\dts\arm\nxp\nxp_mcxw7x_common.dtsi:391 */
					ranges = < 0x0 0x1c0000 0xa000 >; /* in zephyr\dts\arm\nxp\nxp_mcxw71.dtsi:61 */

					/* node '/soc/peripheral@50000000/fast_peripherals1@8800000/smu2@1c0000/memory@8800' defined in zephyr\dts\arm\nxp\nxp_mcxw7x_common.dtsi:393 */
					rpmsgmem: memory@8800 {
						compatible = "zephyr,memory-region",
						             "mmio-sram";              /* in zephyr\dts\arm\nxp\nxp_mcxw7x_common.dtsi:394 */
						reg = < 0x8800 0x1800 >;               /* in zephyr\dts\arm\nxp\nxp_mcxw7x_common.dtsi:395 */
						zephyr,memory-region = "rpmsg_sh_mem"; /* in zephyr\dts\arm\nxp\nxp_mcxw7x_common.dtsi:396 */
						zephyr,memory-attr = < 0x100000 >;     /* in zephyr\dts\arm\nxp\nxp_mcxw7x_common.dtsi:397 */
					};
				};
			};
		};
	};

	/* node '/cpus' defined in zephyr\dts\arm\nxp\nxp_mcxw7x_common.dtsi:27 */
	cpus {
		#address-cells = < 0x1 >; /* in zephyr\dts\arm\nxp\nxp_mcxw7x_common.dtsi:28 */
		#size-cells = < 0x0 >;    /* in zephyr\dts\arm\nxp\nxp_mcxw7x_common.dtsi:29 */

		/* node '/cpus/cpu@0' defined in zephyr\dts\arm\nxp\nxp_mcxw7x_common.dtsi:31 */
		cpu0: cpu@0 {
			compatible = "arm,cortex-m33f"; /* in zephyr\dts\arm\nxp\nxp_mcxw7x_common.dtsi:32 */
			reg = < 0x0 >;                  /* in zephyr\dts\arm\nxp\nxp_mcxw7x_common.dtsi:33 */
			#address-cells = < 0x1 >;       /* in zephyr\dts\arm\nxp\nxp_mcxw7x_common.dtsi:34 */
			#size-cells = < 0x1 >;          /* in zephyr\dts\arm\nxp\nxp_mcxw7x_common.dtsi:35 */

			/* node '/cpus/cpu@0/mpu@e000ed90' defined in zephyr\dts\arm\nxp\nxp_mcxw7x_common.dtsi:37 */
			mpu: mpu@e000ed90 {
				compatible = "arm,armv8m-mpu"; /* in zephyr\dts\arm\nxp\nxp_mcxw7x_common.dtsi:38 */
				reg = < 0xe000ed90 0x40 >;     /* in zephyr\dts\arm\nxp\nxp_mcxw7x_common.dtsi:39 */
			};
		};
	};

	/* node '/pinctrl' defined in zephyr\dts\arm\nxp\nxp_mcxw7x_common.dtsi:103 */
	pinctrl: pinctrl {
		compatible = "nxp,port-pinctrl"; /* in zephyr\dts\arm\nxp\nxp_mcxw7x_common.dtsi:104 */

		/* node '/pinctrl/pinmux_lpuart0' defined in zephyr\boards\nxp\frdm_mcxw71\frdm_mcxw71-pinctrl.dtsi:9 */
		pinmux_lpuart0: pinmux_lpuart0 {
			phandle = < 0x3 >; /* in zephyr\boards\nxp\frdm_mcxw71\frdm_mcxw71.dts:82 */

			/* node '/pinctrl/pinmux_lpuart0/group0' defined in zephyr\boards\nxp\frdm_mcxw71\frdm_mcxw71-pinctrl.dtsi:10 */
			group0 {
				pinmux = < 0x4000600 >,
				         < 0x4400600 >; /* in zephyr\boards\nxp\frdm_mcxw71\frdm_mcxw71-pinctrl.dtsi:11 */
				drive-strength = "low"; /* in zephyr\boards\nxp\frdm_mcxw71\frdm_mcxw71-pinctrl.dtsi:12 */
				slew-rate = "fast";     /* in zephyr\boards\nxp\frdm_mcxw71\frdm_mcxw71-pinctrl.dtsi:13 */
			};
		};

		/* node '/pinctrl/pinmux_lpuart1' defined in zephyr\boards\nxp\frdm_mcxw71\frdm_mcxw71-pinctrl.dtsi:17 */
		pinmux_lpuart1: pinmux_lpuart1 {
			phandle = < 0x4 >; /* in zephyr\boards\nxp\frdm_mcxw71\frdm_mcxw71.dts:89 */

			/* node '/pinctrl/pinmux_lpuart1/group0' defined in zephyr\boards\nxp\frdm_mcxw71\frdm_mcxw71-pinctrl.dtsi:18 */
			group0 {
				pinmux = < 0x20800300 >,
				         < 0x20c00300 >; /* in zephyr\boards\nxp\frdm_mcxw71\frdm_mcxw71-pinctrl.dtsi:19 */
				drive-strength = "low";  /* in zephyr\boards\nxp\frdm_mcxw71\frdm_mcxw71-pinctrl.dtsi:20 */
				slew-rate = "fast";      /* in zephyr\boards\nxp\frdm_mcxw71\frdm_mcxw71-pinctrl.dtsi:21 */
			};
		};

		/* node '/pinctrl/pinmux_tpm0' defined in zephyr\boards\nxp\frdm_mcxw71\frdm_mcxw71-pinctrl.dtsi:25 */
		pinmux_tpm0: pinmux_tpm0 {
			phandle = < 0x9 >; /* in zephyr\boards\nxp\frdm_mcxw71\frdm_mcxw71.dts:164 */

			/* node '/pinctrl/pinmux_tpm0/group0' defined in zephyr\boards\nxp\frdm_mcxw71\frdm_mcxw71-pinctrl.dtsi:26 */
			group0 {
				pinmux = < 0x5400500 >,
				         < 0x5000500 >,
				         < 0x4c00500 >; /* in zephyr\boards\nxp\frdm_mcxw71\frdm_mcxw71-pinctrl.dtsi:27 */
				drive-strength = "low"; /* in zephyr\boards\nxp\frdm_mcxw71\frdm_mcxw71-pinctrl.dtsi:30 */
				slew-rate = "fast";     /* in zephyr\boards\nxp\frdm_mcxw71\frdm_mcxw71-pinctrl.dtsi:31 */
			};
		};

		/* node '/pinctrl/pinmux_lpi2c0' defined in zephyr\boards\nxp\frdm_mcxw71\frdm_mcxw71-pinctrl.dtsi:35 */
		pinmux_lpi2c0: pinmux_lpi2c0 {

			/* node '/pinctrl/pinmux_lpi2c0/group0' defined in zephyr\boards\nxp\frdm_mcxw71\frdm_mcxw71-pinctrl.dtsi:36 */
			group0 {
				pinmux = < 0x4c00400 >,
				         < 0x4800400 >; /* in zephyr\boards\nxp\frdm_mcxw71\frdm_mcxw71-pinctrl.dtsi:37 */
				drive-strength = "low"; /* in zephyr\boards\nxp\frdm_mcxw71\frdm_mcxw71-pinctrl.dtsi:39 */
				slew-rate = "fast";     /* in zephyr\boards\nxp\frdm_mcxw71\frdm_mcxw71-pinctrl.dtsi:40 */
				drive-open-drain;       /* in zephyr\boards\nxp\frdm_mcxw71\frdm_mcxw71-pinctrl.dtsi:41 */
			};
		};

		/* node '/pinctrl/pinmux_lpi2c1' defined in zephyr\boards\nxp\frdm_mcxw71\frdm_mcxw71-pinctrl.dtsi:45 */
		pinmux_lpi2c1: pinmux_lpi2c1 {
			phandle = < 0x5 >; /* in zephyr\boards\nxp\frdm_mcxw71\frdm_mcxw71.dts:95 */

			/* node '/pinctrl/pinmux_lpi2c1/group0' defined in zephyr\boards\nxp\frdm_mcxw71\frdm_mcxw71-pinctrl.dtsi:46 */
			group0 {
				pinmux = < 0x11400400 >,
				         < 0x11000400 >; /* in zephyr\boards\nxp\frdm_mcxw71\frdm_mcxw71-pinctrl.dtsi:47 */
				drive-strength = "low";  /* in zephyr\boards\nxp\frdm_mcxw71\frdm_mcxw71-pinctrl.dtsi:49 */
				slew-rate = "fast";      /* in zephyr\boards\nxp\frdm_mcxw71\frdm_mcxw71-pinctrl.dtsi:50 */
				drive-open-drain;        /* in zephyr\boards\nxp\frdm_mcxw71\frdm_mcxw71-pinctrl.dtsi:51 */
			};
		};

		/* node '/pinctrl/pinmux_lpspi1' defined in zephyr\boards\nxp\frdm_mcxw71\frdm_mcxw71-pinctrl.dtsi:55 */
		pinmux_lpspi1: pinmux_lpspi1 {
			phandle = < 0x6 >; /* in zephyr\boards\nxp\frdm_mcxw71\frdm_mcxw71.dts:107 */

			/* node '/pinctrl/pinmux_lpspi1/group0' defined in zephyr\boards\nxp\frdm_mcxw71\frdm_mcxw71-pinctrl.dtsi:56 */
			group0 {
				pinmux = < 0x10400200 >,
				         < 0x10800200 >,
				         < 0x10c00200 >,
				         < 0x10000200 >; /* in zephyr\boards\nxp\frdm_mcxw71\frdm_mcxw71-pinctrl.dtsi:57 */
				slew-rate = "fast";      /* in zephyr\boards\nxp\frdm_mcxw71\frdm_mcxw71-pinctrl.dtsi:61 */
				drive-strength = "low";  /* in zephyr\boards\nxp\frdm_mcxw71\frdm_mcxw71-pinctrl.dtsi:62 */
			};
		};

		/* node '/pinctrl/pinmux_flexcan' defined in zephyr\boards\nxp\frdm_mcxw71\frdm_mcxw71-pinctrl.dtsi:66 */
		pinmux_flexcan: pinmux_flexcan {
			phandle = < 0xa >; /* in zephyr\boards\nxp\frdm_mcxw71\frdm_mcxw71.dts:174 */

			/* node '/pinctrl/pinmux_flexcan/group0' defined in zephyr\boards\nxp\frdm_mcxw71\frdm_mcxw71-pinctrl.dtsi:67 */
			group0 {
				pinmux = < 0x21400300 >,
				         < 0x21000300 >; /* in zephyr\boards\nxp\frdm_mcxw71\frdm_mcxw71-pinctrl.dtsi:68 */
				slew-rate = "slow";      /* in zephyr\boards\nxp\frdm_mcxw71\frdm_mcxw71-pinctrl.dtsi:69 */
				drive-strength = "low";  /* in zephyr\boards\nxp\frdm_mcxw71\frdm_mcxw71-pinctrl.dtsi:70 */
			};
		};

		/* node '/pinctrl/pinmux_lpadc0' defined in zephyr\boards\nxp\frdm_mcxw71\frdm_mcxw71-pinctrl.dtsi:74 */
		pinmux_lpadc0: pinmux_lpadc0 {
			phandle = < 0xc >; /* in zephyr\boards\nxp\frdm_mcxw71\frdm_mcxw71.dts:183 */

			/* node '/pinctrl/pinmux_lpadc0/group0' defined in zephyr\boards\nxp\frdm_mcxw71\frdm_mcxw71-pinctrl.dtsi:75 */
			group0 {
				pinmux = < 0x30800000 >,
				         < 0x30c00000 >,
				         < 0x30400000 >; /* in zephyr\boards\nxp\frdm_mcxw71\frdm_mcxw71-pinctrl.dtsi:76 */
				drive-strength = "low";  /* in zephyr\boards\nxp\frdm_mcxw71\frdm_mcxw71-pinctrl.dtsi:79 */
				slew-rate = "fast";      /* in zephyr\boards\nxp\frdm_mcxw71\frdm_mcxw71-pinctrl.dtsi:80 */
			};
		};
	};

	/* node '/user_led' defined in zephyr\boards\nxp\frdm_mcxw71\frdm_mcxw71.dts:36 */
	user_led {
		compatible = "gpio-leds"; /* in zephyr\boards\nxp\frdm_mcxw71\frdm_mcxw71.dts:37 */

		/* node '/user_led/led' defined in zephyr\boards\nxp\frdm_mcxw71\frdm_mcxw71.dts:38 */
		blue_led: led {
			gpios = < &gpioc 0x1 0x1 >; /* in zephyr\boards\nxp\frdm_mcxw71\frdm_mcxw71.dts:39 */
		};
	};

	/* node '/pwmleds' defined in zephyr\boards\nxp\frdm_mcxw71\frdm_mcxw71.dts:43 */
	pwmleds {
		compatible = "pwm-leds"; /* in zephyr\boards\nxp\frdm_mcxw71\frdm_mcxw71.dts:44 */

		/* node '/pwmleds/pwm_led_0' defined in zephyr\boards\nxp\frdm_mcxw71\frdm_mcxw71.dts:45 */
		blue_pwm_led: pwm_led_0 {
			pwms = < &tpm0 0x1 0x1312d00 0x1 >; /* in zephyr\boards\nxp\frdm_mcxw71\frdm_mcxw71.dts:46 */
		};

		/* node '/pwmleds/pwm_led_1' defined in zephyr\boards\nxp\frdm_mcxw71\frdm_mcxw71.dts:48 */
		green_pwm_led: pwm_led_1 {
			pwms = < &tpm0 0x2 0x1312d00 0x1 >; /* in zephyr\boards\nxp\frdm_mcxw71\frdm_mcxw71.dts:49 */
		};

		/* node '/pwmleds/pwm_led_2' defined in zephyr\boards\nxp\frdm_mcxw71\frdm_mcxw71.dts:51 */
		red_pwm_led: pwm_led_2 {
			pwms = < &tpm0 0x0 0x1312d00 0x1 >; /* in zephyr\boards\nxp\frdm_mcxw71\frdm_mcxw71.dts:52 */
		};
	};

	/* node '/gpio_keys' defined in zephyr\boards\nxp\frdm_mcxw71\frdm_mcxw71.dts:56 */
	gpio_keys {
		compatible = "gpio-keys"; /* in zephyr\boards\nxp\frdm_mcxw71\frdm_mcxw71.dts:57 */

		/* node '/gpio_keys/button_0' defined in zephyr\boards\nxp\frdm_mcxw71\frdm_mcxw71.dts:58 */
		user_button_0: button_0 {
			label = "User SW2";          /* in zephyr\boards\nxp\frdm_mcxw71\frdm_mcxw71.dts:59 */
			gpios = < &gpioc 0x6 0x11 >; /* in zephyr\boards\nxp\frdm_mcxw71\frdm_mcxw71.dts:60 */
			zephyr,code = < 0xb >;       /* in zephyr\boards\nxp\frdm_mcxw71\frdm_mcxw71.dts:61 */
			status = "okay";             /* in zephyr\boards\nxp\frdm_mcxw71\frdm_mcxw71.dts:62 */
		};
	};
};
